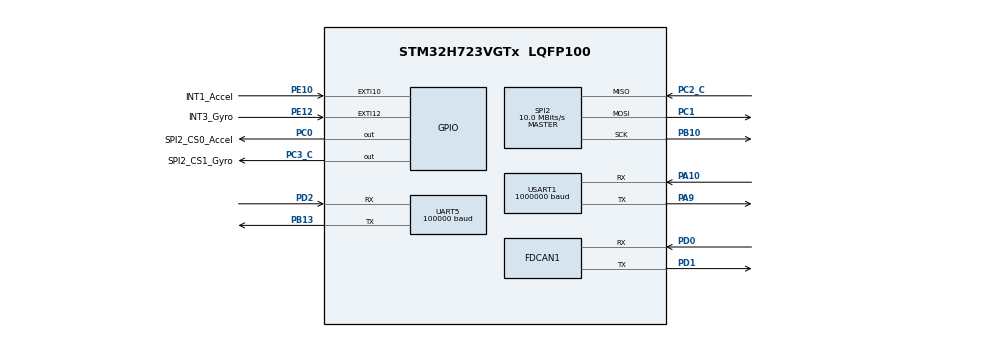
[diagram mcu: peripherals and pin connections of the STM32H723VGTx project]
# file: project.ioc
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CORTEX_M7.default_mode_Activation=1
Dma.Request0=UART5_RX
Dma.Request1=USART1_RX
Dma.Request2=USART1_TX
Dma.Request3=SPI2_RX
Dma.Request4=SPI2_TX
Dma.SPI2_RX.3.Direction=DMA_PERIPH_TO_MEMORY
Dma.SPI2_RX.3.EventEnable=DISABLE
Dma.SPI2_RX.3.FIFOMode=DMA_FIFOMODE_DISABLE
Dma.SPI2_RX.3.Instance=DMA1_Stream3
Dma.SPI2_RX.3.MemDataAlignment=DMA_MDATAALIGN_BYTE
Dma.SPI2_RX.3.MemInc=DMA_MINC_ENABLE
Dma.SPI2_RX.3.Mode=DMA_NORMAL
Dma.SPI2_RX.3.PeriphDataAlignment=DMA_PDATAALIGN_BYTE
Dma.SPI2_RX.3.PeriphInc=DMA_PINC_DISABLE
Dma.SPI2_RX.3.Polarity=HAL_DMAMUX_REQ_GEN_RISING
Dma.SPI2_RX.3.Priority=DMA_PRIORITY_HIGH
Dma.SPI2_RX.3.RequestNumber=1
Dma.SPI2_RX.3.SignalID=NONE
Dma.SPI2_RX.3.SyncEnable=DISABLE
Dma.SPI2_RX.3.SyncPolarity=HAL_DMAMUX_SYNC_NO_EVENT
Dma.SPI2_RX.3.SyncRequestNumber=1
Dma.SPI2_RX.3.SyncSignalID=NONE
Dma.SPI2_TX.4.Direction=DMA_MEMORY_TO_PERIPH
Dma.SPI2_TX.4.EventEnable=DISABLE
Dma.SPI2_TX.4.FIFOMode=DMA_FIFOMODE_DISABLE
Dma.SPI2_TX.4.Instance=DMA1_Stream4
Dma.SPI2_TX.4.MemDataAlignment=DMA_MDATAALIGN_BYTE
Dma.SPI2_TX.4.MemInc=DMA_MINC_ENABLE
Dma.SPI2_TX.4.Mode=DMA_NORMAL
Dma.SPI2_TX.4.PeriphDataAlignment=DMA_PDATAALIGN_BYTE
Dma.SPI2_TX.4.PeriphInc=DMA_PINC_DISABLE
Dma.SPI2_TX.4.Polarity=HAL_DMAMUX_REQ_GEN_RISING
Dma.SPI2_TX.4.Priority=DMA_PRIORITY_HIGH
Dma.SPI2_TX.4.RequestNumber=1
Dma.SPI2_TX.4.SignalID=NONE
Dma.SPI2_TX.4.SyncEnable=DISABLE
Dma.SPI2_TX.4.SyncPolarity=HAL_DMAMUX_SYNC_NO_EVENT
Dma.SPI2_TX.4.SyncRequestNumber=1
Dma.SPI2_TX.4.SyncSignalID=NONE
Dma.UART5_RX.0.Direction=DMA_PERIPH_TO_MEMORY
Dma.UART5_RX.0.EventEnable=DISABLE
Dma.UART5_RX.0.FIFOMode=DMA_FIFOMODE_DISABLE
Dma.UART5_RX.0.Instance=DMA1_Stream0
Dma.UART5_RX.0.MemDataAlignment=DMA_MDATAALIGN_BYTE
Dma.UART5_RX.0.MemInc=DMA_MINC_ENABLE
Dma.UART5_RX.0.Mode=DMA_NORMAL
Dma.UART5_RX.0.PeriphDataAlignment=DMA_PDATAALIGN_BYTE
Dma.UART5_RX.0.PeriphInc=DMA_PINC_DISABLE
Dma.UART5_RX.0.Polarity=HAL_DMAMUX_REQ_GEN_RISING
Dma.UART5_RX.0.Priority=DMA_PRIORITY_VERY_HIGH
Dma.UART5_RX.0.RequestNumber=1
Dma.UART5_RX.0.SignalID=NONE
Dma.UART5_RX.0.SyncEnable=DISABLE
Dma.UART5_RX.0.SyncPolarity=HAL_DMAMUX_SYNC_NO_EVENT
Dma.UART5_RX.0.SyncRequestNumber=1
Dma.UART5_RX.0.SyncSignalID=NONE
Dma.USART1_RX.1.Direction=DMA_PERIPH_TO_MEMORY
Dma.USART1_RX.1.EventEnable=DISABLE
Dma.USART1_RX.1.FIFOMode=DMA_FIFOMODE_DISABLE
Dma.USART1_RX.1.Instance=DMA1_Stream1
Dma.USART1_RX.1.MemDataAlignment=DMA_MDATAALIGN_BYTE
Dma.USART1_RX.1.MemInc=DMA_MINC_ENABLE
Dma.USART1_RX.1.Mode=DMA_NORMAL
Dma.USART1_RX.1.PeriphDataAlignment=DMA_PDATAALIGN_BYTE
Dma.USART1_RX.1.PeriphInc=DMA_PINC_DISABLE
Dma.USART1_RX.1.Polarity=HAL_DMAMUX_REQ_GEN_RISING
Dma.USART1_RX.1.Priority=DMA_PRIORITY_LOW
Dma.USART1_RX.1.RequestNumber=1
Dma.USART1_RX.1.SignalID=NONE
Dma.USART1_RX.1.SyncEnable=DISABLE
Dma.USART1_RX.1.SyncPolarity=HAL_DMAMUX_SYNC_NO_EVENT
Dma.USART1_RX.1.SyncRequestNumber=1
Dma.USART1_RX.1.SyncSignalID=NONE
Dma.USART1_TX.2.Direction=DMA_MEMORY_TO_PERIPH
Dma.USART1_TX.2.EventEnable=DISABLE
Dma.USART1_TX.2.FIFOMode=DMA_FIFOMODE_DISABLE
Dma.USART1_TX.2.Instance=DMA1_Stream2
Dma.USART1_TX.2.MemDataAlignment=DMA_MDATAALIGN_BYTE
Dma.USART1_TX.2.MemInc=DMA_MINC_ENABLE
Dma.USART1_TX.2.Mode=DMA_NORMAL
Dma.USART1_TX.2.PeriphDataAlignment=DMA_PDATAALIGN_BYTE
Dma.USART1_TX.2.PeriphInc=DMA_PINC_DISABLE
Dma.USART1_TX.2.Polarity=HAL_DMAMUX_REQ_GEN_RISING
Dma.USART1_TX.2.Priority=DMA_PRIORITY_LOW
Dma.USART1_TX.2.RequestNumber=1
Dma.USART1_TX.2.SignalID=NONE
Dma.USART1_TX.2.SyncEnable=DISABLE
Dma.USART1_TX.2.SyncPolarity=HAL_DMAMUX_SYNC_NO_EVENT
Dma.USART1_TX.2.SyncRequestNumber=1
Dma.USART1_TX.2.SyncSignalID=NONE
FDCAN1.AutoRetransmission=ENABLE
FDCAN1.CalculateBaudRateNominal=800000
FDCAN1.CalculateTimeBitNominal=1250
FDCAN1.CalculateTimeQuantumNominal=31.25
FDCAN1.DataPrescaler=3
FDCAN1.DataSyncJumpWidth=10
FDCAN1.DataTimeSeg1=29
FDCAN1.NominalPrescaler=3
FDCAN1.NominalSyncJumpWidth=10
FDCAN1.NominalTimeSeg1=29
FDCAN1.NominalTimeSeg2=10
FDCAN1.ProtocolException=ENABLE
FDCAN1.RxFifo0ElmtsNbr=8
FDCAN1.RxFifo1ElmtsNbr=8
FDCAN1.StdFiltersNbr=0x00000000
FDCAN1.TxFifoQueueElmtsNbr=8
Mcu.Family=STM32H7
Mcu.Name=STM32H723VGTx
Mcu.Package=LQFP100
NVIC.DMA1_Stream0_IRQn=true\:0\:0\:false\:false\:true\:false\:true\:true
NVIC.DMA1_Stream1_IRQn=true\:0\:0\:false\:false\:true\:false\:true\:true
NVIC.DMA1_Stream2_IRQn=true\:0\:0\:false\:false\:true\:false\:true\:true
NVIC.DMA1_Stream3_IRQn=true\:0\:0\:false\:false\:true\:false\:true\:true
NVIC.DMA1_Stream4_IRQn=true\:0\:0\:false\:false\:true\:false\:true\:true
NVIC.EXTI15_10_IRQn=true\:0\:0\:false\:false\:true\:true\:true\:true
NVIC.FDCAN1_IT0_IRQn=true\:0\:0\:false\:false\:true\:true\:true\:true
NVIC.FDCAN1_IT1_IRQn=true\:0\:0\:false\:false\:true\:true\:true\:true
NVIC.PriorityGroup=NVIC_PRIORITYGROUP_4
NVIC.SPI2_IRQn=true\:0\:0\:false\:false\:true\:false\:true\:true
NVIC.UART5_IRQn=true\:0\:0\:false\:false\:true\:true\:true\:true
NVIC.USART1_IRQn=true\:0\:0\:false\:false\:true\:true\:true\:true
PA10.Mode=Asynchronous
PA10.Signal=USART1_RX
PA13(JTMS/SWDIO).Mode=Serial_Wire
PA13(JTMS/SWDIO).Signal=DEBUG_JTMS-SWDIO
PA14(JTCK/SWCLK).Mode=Serial_Wire
PA14(JTCK/SWCLK).Signal=DEBUG_JTCK-SWCLK
PA9.Mode=Asynchronous
PA9.Signal=USART1_TX
PB10.Mode=Full_Duplex_Master
PB10.Signal=SPI2_SCK
PB13.Mode=Asynchronous
PB13.Signal=UART5_TX
PC0.GPIO_Label=SPI2_CS0_Accel
PC0.Signal=GPIO_Output
PC1.Mode=Full_Duplex_Master
PC1.Signal=SPI2_MOSI
PC2_C.Mode=Full_Duplex_Master
PC2_C.Signal=SPI2_MISO
PC3_C.GPIO_Label=SPI2_CS1_Gyro
PC3_C.Signal=GPIO_Output
PD0.Mode=FDCAN_Activate
PD0.Signal=FDCAN1_RX
PD1.Mode=FDCAN_Activate
PD1.Signal=FDCAN1_TX
PD2.Mode=Asynchronous
PD2.Signal=UART5_RX
PE10.GPIO_Label=INT1_Accel
PE10.Signal=GPXTI10
PE12.GPIO_Label=INT3_Gyro
PE12.Signal=GPXTI12
PH0-OSC_IN.Mode=HSE-External-Oscillator
PH0-OSC_IN.Signal=RCC_OSC_IN
PH1-OSC_OUT.Mode=HSE-External-Oscillator
PH1-OSC_OUT.Signal=RCC_OSC_OUT
ProjectManager.HeapSize=0x200
ProjectManager.StackSize=0x400
ProjectManager.TargetToolchain=STM32CubeIDE
RCC.ADCFreq_Value=48375000
RCC.APB1Freq_Value=48000000
RCC.APB2Freq_Value=96000000
RCC.APB3Freq_Value=96000000
RCC.APB4Freq_Value=96000000
RCC.CortexFreq_Value=192000000
RCC.D1PPRE=RCC_APB3_DIV2
RCC.D2PPRE1=RCC_APB1_DIV4
RCC.D2PPRE2=RCC_APB2_DIV2
RCC.D3PPRE=RCC_APB4_DIV2
RCC.DIVM1=2
RCC.DIVM3=2
RCC.DIVN1=16
RCC.DIVN3=20
RCC.DIVP1=1
RCC.DIVP3=3
RCC.HCLKFreq_Value=192000000
RCC.HSE_VALUE=24000000
RCC.PLL3FRACN=0
RCC.PLLFRACN=0
RCC.PLLSourceVirtual=RCC_PLLSOURCE_HSE
RCC.SPI123CLockSelection=RCC_SPI123CLKSOURCE_PLL3
RCC.SYSCLKFreq_VALUE=192000000
RCC.SYSCLKSource=RCC_SYSCLKSOURCE_PLLCLK
RCC.USBFreq_Value=96000000
SPI2.BaudRatePrescaler=SPI_BAUDRATEPRESCALER_8
SPI2.CLKPhase=SPI_PHASE_2EDGE
SPI2.CLKPolarity=SPI_POLARITY_HIGH
SPI2.CalculateBaudRate=10.0 MBits/s
SPI2.DataSize=SPI_DATASIZE_8BIT
SPI2.Direction=SPI_DIRECTION_2LINES
SPI2.Mode=SPI_MODE_MASTER
SPI2.VirtualType=VM_MASTER
STMicroelectronics.X-CUBE-ALGOBUILD.1.4.0.LibraryCcDSPOoLibraryJjDSPOoLibrary=true
UART5.BaudRate=100000
UART5.Mode=MODE_RX
UART5.StopBits=UART_STOPBITS_2
UART5.WordLength=WORDLENGTH_9B
USART1.BaudRate=1000000
USART1.VirtualMode-Asynchronous=VM_ASYNC
VP_MEMORYMAP_VS_MEMORYMAP.Mode=CurAppReg
VP_STMicroelectronics.X-CUBE-ALGOBUILD_VS_DSPOoLibraryJjLibrary_1.4.0_1.4.0.Mode=DSPOoLibraryJjLibrary
board=custom

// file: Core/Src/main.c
/* USER CODE BEGIN Header */
/**
  ******************************************************************************
  * @file           : main.c
  * @brief          : Main program body
  ******************************************************************************
  * @attention
  *
  * Copyright (c) 2025 STMicroelectronics.
  * All rights reserved.
  *
  * This software is licensed under terms that can be found in the LICENSE file
  * in the root directory of this software component.
  * If no LICENSE file comes with this software, it is provided AS-IS.
  *
  ******************************************************************************
  */
/* USER CODE END Header */
#include "main.h"
#include "dma.h"
#include "fdcan.h"
#include "memorymap.h"
#include "spi.h"
#include "usart.h"
#include "gpio.h"

/* USER CODE BEGIN Includes */
#include "Robot/Task/task.h"
/* USER CODE END Includes */

void SystemClock_Config(void);
static void MPU_Config(void);

int main(void)
{

  /* MPU Configuration--------------------------------------------------------*/
  MPU_Config();

  /* MCU Configuration--------------------------------------------------------*/

  /* Reset of all peripherals, Initializes the Flash interface and the Systick. */
  HAL_Init();

  /* Configure the system clock */
  SystemClock_Config();

  /* Initialize all configured peripherals */
  MX_GPIO_Init();
  MX_DMA_Init();
  MX_FDCAN1_Init();
  MX_UART5_Init();
  MX_USART1_UART_Init();
  MX_SPI2_Init();
  /* USER CODE BEGIN 2 */
  Task_Init();
  /* USER CODE END 2 */

  /* Infinite loop */
  /* USER CODE BEGIN WHILE */
  while (1)
  {
    Task();
    /* USER CODE END WHILE */

  }
}

void SystemClock_Config(void)
{
  RCC_OscInitTypeDef RCC_OscInitStruct = {0};
  RCC_ClkInitTypeDef RCC_ClkInitStruct = {0};

  /** Supply configuration update enable
  */
  HAL_PWREx_ConfigSupply(PWR_LDO_SUPPLY);

  /** Configure the main internal regulator output voltage
  */
  __HAL_PWR_VOLTAGESCALING_CONFIG(PWR_REGULATOR_VOLTAGE_SCALE1);

  while(!__HAL_PWR_GET_FLAG(PWR_FLAG_VOSRDY)) {}

  /** Initializes the RCC Oscillators according to the specified parameters
  * in the RCC_OscInitTypeDef structure.
  */
  RCC_OscInitStruct.OscillatorType = RCC_OSCILLATORTYPE_HSE;
  RCC_OscInitStruct.HSEState = RCC_HSE_ON;
  RCC_OscInitStruct.PLL.PLLState = RCC_PLL_ON;
  RCC_OscInitStruct.PLL.PLLSource = RCC_PLLSOURCE_HSE;
  RCC_OscInitStruct.PLL.PLLM = 2;
  RCC_OscInitStruct.PLL.PLLN = 16;
  RCC_OscInitStruct.PLL.PLLP = 1;
  RCC_OscInitStruct.PLL.PLLQ = 2;
  RCC_OscInitStruct.PLL.PLLR = 2;
  RCC_OscInitStruct.PLL.PLLRGE = RCC_PLL1VCIRANGE_3;
  RCC_OscInitStruct.PLL.PLLVCOSEL = RCC_PLL1VCOWIDE;
  RCC_OscInitStruct.PLL.PLLFRACN = 0;
  if (HAL_RCC_OscConfig(&RCC_OscInitStruct) != HAL_OK)
  {
    Error_Handler();
  }

  /** Initializes the CPU, AHB and APB buses clocks
  */
  RCC_ClkInitStruct.ClockType = RCC_CLOCKTYPE_HCLK|RCC_CLOCKTYPE_SYSCLK
                              |RCC_CLOCKTYPE_PCLK1|RCC_CLOCKTYPE_PCLK2
                              |RCC_CLOCKTYPE_D3PCLK1|RCC_CLOCKTYPE_D1PCLK1;
  RCC_ClkInitStruct.SYSCLKSource = RCC_SYSCLKSOURCE_PLLCLK;
  RCC_ClkInitStruct.SYSCLKDivider = RCC_SYSCLK_DIV1;
  RCC_ClkInitStruct.AHBCLKDivider = RCC_HCLK_DIV1;
  RCC_ClkInitStruct.APB3CLKDivider = RCC_APB3_DIV2;
  RCC_ClkInitStruct.APB1CLKDivider = RCC_APB1_DIV4;
  RCC_ClkInitStruct.APB2CLKDivider = RCC_APB2_DIV2;
  RCC_ClkInitStruct.APB4CLKDivider = RCC_APB4_DIV2;

  if (HAL_RCC_ClockConfig(&RCC_ClkInitStruct, FLASH_LATENCY_2) != HAL_OK)
  {
    Error_Handler();
  }
}

 /* MPU Configuration */

void MPU_Config(void)
{
  MPU_Region_InitTypeDef MPU_InitStruct = {0};

  /* Disables the MPU */
  HAL_MPU_Disable();

  /** Initializes and configures the Region and the memory to be protected
  */
  MPU_InitStruct.Enable = MPU_REGION_ENABLE;
  MPU_InitStruct.Number = MPU_REGION_NUMBER0;
  MPU_InitStruct.BaseAddress = 0x0;
  MPU_InitStruct.Size = MPU_REGION_SIZE_4GB;
  MPU_InitStruct.SubRegionDisable = 0x87;
  MPU_InitStruct.TypeExtField = MPU_TEX_LEVEL0;
  MPU_InitStruct.AccessPermission = MPU_REGION_NO_ACCESS;
  MPU_InitStruct.DisableExec = MPU_INSTRUCTION_ACCESS_DISABLE;
  MPU_InitStruct.IsShareable = MPU_ACCESS_SHAREABLE;
  MPU_InitStruct.IsCacheable = MPU_ACCESS_NOT_CACHEABLE;
  MPU_InitStruct.IsBufferable = MPU_ACCESS_NOT_BUFFERABLE;

  HAL_MPU_ConfigRegion(&MPU_InitStruct);
  /* Enables the MPU */
  HAL_MPU_Enable(MPU_PRIVILEGED_DEFAULT);

}

void Error_Handler(void)
{
  __disable_irq();
  while (1)
  {
  }
}
